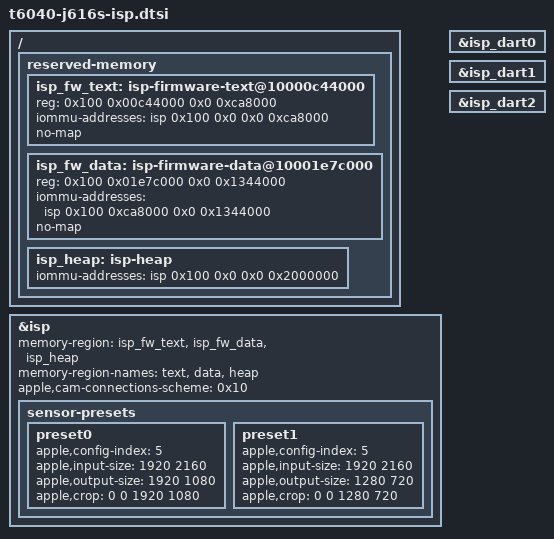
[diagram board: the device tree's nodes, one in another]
// SPDX-License-Identifier: GPL-2.0+ OR MIT
/*
 * The J616s front camera: an IMX958 behind the ISP.
 *
 * iBoot loads the ISP firmware below the kernel's memory. Its segments are
 * the ADT's isp0 segment-ranges (macOS 26.6.2, iBoot mBoot-18000.161.10),
 * mapped where the firmware runs them: 0x100_0000_0000 onwards, its 32 MiB
 * main memory. The driver checks that the coprocessor's reset vector is this
 * text before it starts the firmware.
 */

/ {
	reserved-memory {
		#address-cells = <2>;
		#size-cells = <2>;
		ranges;

		isp_fw_text: isp-firmware-text@10000c44000 {
			reg = <0x100 0x00c44000 0x0 0xca8000>;
			iommu-addresses = <&isp 0x100 0x0 0x0 0xca8000>;
			no-map;
		};

		isp_fw_data: isp-firmware-data@10001e7c000 {
			reg = <0x100 0x01e7c000 0x0 0x1344000>;
			iommu-addresses = <&isp 0x100 0xca8000 0x0 0x1344000>;
			no-map;
		};

		/* the firmware's main memory, the driver allocates above it */
		isp_heap: isp-heap {
			iommu-addresses = <&isp 0x100 0x0 0x0 0x2000000>;
		};
	};
};

&isp {
	memory-region = <&isp_fw_text>, <&isp_fw_data>, <&isp_heap>;
	memory-region-names = "text", "data", "heap";
	/* ADT isp0 cam-connections-scheme */
	apple,cam-connections-scheme = <0x10>;
	status = "okay";

	/*
	 * Firmware configuration 5 as the firmware reports it, at the output
	 * sizes and crops aurora's J616s captures used.
	 */
	sensor-presets {
		/* 1920x1080 */
		preset0 {
			apple,config-index = <5>;
			apple,input-size = <1920 2160>;
			apple,output-size = <1920 1080>;
			apple,crop = <0 0 1920 1080>;
		};
		/* 1280x720 */
		preset1 {
			apple,config-index = <5>;
			apple,input-size = <1920 2160>;
			apple,output-size = <1280 720>;
			apple,crop = <0 0 1280 720>;
		};
	};
};

&isp_dart0 {
	status = "okay";
};

&isp_dart1 {
	status = "okay";
};

&isp_dart2 {
	status = "okay";
};
